AUTOSAR XML (schema 4-0-3)
package /Svc_IoHwAb/CompuMethods
  compu method IoHwAb_Cm_EdgeEnum: 1=IOHWAB_RISING_EDGE (IoHwAb_RisingEdge), 2=IOHWAB_FALLING_EDGE (IoHwAb_FallingEdge), 3=IOHWAB_BOTH_EDGES (IoHwAb_BothEdges)
package /Svc_IoHwAb/ImplementationDataTypes
  20 x impl type:
    IoHwAb_IcuDutyCycleType: category=STRUCTURE
      element ActiveTime: implementation-data-type=IoHwAb_IcuValueType
      element PeriodTime: implementation-data-type=IoHwAb_IcuValueType
    IoHwAb_OcuReturnType: category=VALUE, base-type=uint8
    IoHwAb_GptValueType: category=VALUE, base-type=uint32
    IoHwAb_LengthType: category=VALUE, base-type=uint8
    IoHwAb_OcuValueType: category=VALUE, base-type=uint16
    IoHwAb_ThresholdType: category=VALUE, base-type=uint8
    IoHwAb_IcuEdgeNumberType: category=VALUE, base-type=uint32
    IoHwAb_BoolType: category=VALUE, base-type=uint8, compu {0=IOHWAB_FALSE (IoHwAb_False), 1=IOHWAB_TRUE (IoHwAb_True)}
    IoHwAb_IcuValueType: category=VALUE, base-type=uint32
    IoHwAb_IcuActivationType: category=VALUE, base-type=uint8, compu-method=IoHwAb_Cm_EdgeEnum
    IoHwAb_IcuStateType: category=VALUE, base-type=uint8, compu {0=IOHWAB_IDLE (IoHwAb_Idle), 1=IOHWAB_ACTIVE (IoHwAb_Active)}
    IoHwAb_OcuPinStateType: category=VALUE, base-type=uint8
    IoHwAb_PwmPeriodType: category=VALUE, base-type=uint32
    IoHwAb_IndexType: category=VALUE, base-type=uint16
    IoHwAb_LevelType: category=VALUE, base-type=uint8, compu {0=IOHWAB_LOW (IoHwAb_Low), 1=IOHWAB_HIGH (IoHwAb_High)}
    IoHwAb_ValueType: category=VALUE, base-type=uint16
    IoHwAb_PwmEdgeType: category=VALUE, base-type=uint8, compu-method=IoHwAb_Cm_EdgeEnum
    IoHwAb_IcuIndexType: category=VALUE, base-type=uint16
    IoHwAb_OcuPinActionType: category=VALUE, base-type=uint8
    IoHwAb_StatusType: category=VALUE, base-type=uint8, compu {0=IOHWAB_VOLMON_IoHwAbVoltageMonThreshold0 (IoHwAb_VolMon_IoHwAbVoltageMonThreshold0), 1=IOHWAB_VOLMON_IoHwAbVoltageMonThreshold1 (IoHwAb_VolMon_IoHwAbVoltageMonThreshold1)}
package /Svc_IoHwAb/ClientServerInterfaces
  7 x client server interface, all with is-service=true:
    IoHwAb_If_DigDir
      6 x operation:
        ReadDirect
          arg Level: type=IoHwAb_LevelType, direction=OUT, server-argument-impl-policy=USE-ARGUMENT-TYPE
        WriteDirect
          arg Level: type=IoHwAb_LevelType, direction=IN, server-argument-impl-policy=USE-ARGUMENT-TYPE
        SetToInput
        SetToOutput
        IsInput
          arg blResult: type=IoHwAb_BoolType, direction=OUT, server-argument-impl-policy=USE-ARGUMENT-TYPE
        IsOutput
          arg blResult: type=IoHwAb_BoolType, direction=OUT, server-argument-impl-policy=USE-ARGUMENT-TYPE
    IoHwAb_If_AnaInDir
      operation ReadDirect: possible-error=[IoHwAb_If_AnaInDir/E_BUSY, E_WRONG_LENGTH, E_SETUP_BUFFER_FAIL]
        arg Value: type=IoHwAb_ValueType, direction=OUT, server-argument-impl-policy=USE-ARGUMENT-TYPE
        arg AnaInDirLength: type=IoHwAb_LengthType, direction=IN, server-argument-impl-policy=USE-ARGUMENT-TYPE
      error E_BUSY: error-code=4
      error E_WRONG_LENGTH: error-code=5
      error E_SETUP_BUFFER_FAIL: error-code=6
    IoHwAb_If_AnaIn
      operation Read
        arg Value: type=IoHwAb_ValueType, direction=OUT, server-argument-impl-policy=USE-ARGUMENT-TYPE
      operation Freeze
      operation Unfreeze
      error E_BUSY: error-code=7
    IoHwAb_If_VolMon
      5 x operation:
        Read
          arg Value: type=IoHwAb_ValueType, direction=OUT, server-argument-impl-policy=USE-ARGUMENT-TYPE
        GetStatus
          arg VolMonStatus: type=IoHwAb_StatusType, direction=OUT, server-argument-impl-policy=USE-ARGUMENT-TYPE
        IsThresholdOver
          arg Threshold: type=IoHwAb_ThresholdType, direction=IN, server-argument-impl-policy=USE-ARGUMENT-TYPE
          arg VolMonResult: type=IoHwAb_BoolType, direction=OUT, server-argument-impl-policy=USE-ARGUMENT-TYPE
        IsThresholdUnder
          arg Threshold: type=IoHwAb_ThresholdType, direction=IN, server-argument-impl-policy=USE-ARGUMENT-TYPE
          arg VolMonResult: type=IoHwAb_BoolType, direction=OUT, server-argument-impl-policy=USE-ARGUMENT-TYPE
        Notification
    IoHwAb_If_Icu
      18 x operation:
        SetActivationCondition: possible-error=IoHwAb_If_Icu/E_NOT_SUPPORTED
          arg Activation: type=IoHwAb_IcuActivationType, direction=IN, server-argument-impl-policy=USE-ARGUMENT-TYPE
        DisableNotification: possible-error=IoHwAb_If_Icu/E_NOT_SUPPORTED
        EnableNotification: possible-error=IoHwAb_If_Icu/E_NOT_SUPPORTED
        GetInputState: possible-error=IoHwAb_If_Icu/E_NOT_SUPPORTED
          arg State: type=IoHwAb_IcuStateType, direction=OUT, server-argument-impl-policy=USE-ARGUMENT-TYPE
        StartTimestamp: possible-error=IoHwAb_If_Icu/E_NOT_SUPPORTED
          arg BufPtr: type=IoHwAb_IcuValueType, direction=OUT, server-argument-impl-policy=USE-ARGUMENT-TYPE
          arg BufSize: type=uint16, direction=IN, server-argument-impl-policy=USE-ARGUMENT-TYPE
          arg NotiItv: type=uint16, direction=IN, server-argument-impl-policy=USE-ARGUMENT-TYPE
        StopTimestamp: possible-error=IoHwAb_If_Icu/E_NOT_SUPPORTED
        GetTimestampIndex: possible-error=IoHwAb_If_Icu/E_NOT_SUPPORTED
          arg TimestampIdx: type=IoHwAb_IcuIndexType, direction=OUT, server-argument-impl-policy=USE-ARGUMENT-TYPE
        ResetEdgeCount: possible-error=IoHwAb_If_Icu/E_NOT_SUPPORTED
        EnableEdgeCount: possible-error=IoHwAb_If_Icu/E_NOT_SUPPORTED
        DisableEdgeCount: possible-error=IoHwAb_If_Icu/E_NOT_SUPPORTED
        GetEdgeNumbers: possible-error=IoHwAb_If_Icu/E_NOT_SUPPORTED
          arg Num: type=IoHwAb_IcuEdgeNumberType, direction=OUT, server-argument-impl-policy=USE-ARGUMENT-TYPE
        EnableEdgeDetection: possible-error=IoHwAb_If_Icu/E_NOT_SUPPORTED
        DisableEdgeDetection: possible-error=IoHwAb_If_Icu/E_NOT_SUPPORTED
        StartSignalMeasurement: possible-error=IoHwAb_If_Icu/E_NOT_SUPPORTED
        StopSignalMeasurement: possible-error=IoHwAb_If_Icu/E_NOT_SUPPORTED
        GetTimeElapsed: possible-error=IoHwAb_If_Icu/E_NOT_SUPPORTED
          arg Time: type=IoHwAb_IcuValueType, direction=OUT, server-argument-impl-policy=USE-ARGUMENT-TYPE
        GetDutyCycleValues: possible-error=IoHwAb_If_Icu/E_NOT_SUPPORTED
          arg DutyCycle: type=IoHwAb_IcuDutyCycleType, direction=OUT, server-argument-impl-policy=USE-ARGUMENT-TYPE
        Notification
      error E_NOT_SUPPORTED: error-code=9
    IoHwAb_If_Gpt
      7 x operation:
        StartTimer: possible-error=IoHwAb_If_Gpt/E_NOT_SUPPORTED
          arg Value: type=IoHwAb_GptValueType, direction=IN, server-argument-impl-policy=USE-ARGUMENT-TYPE
        StopTimer: possible-error=IoHwAb_If_Gpt/E_NOT_SUPPORTED
        GetTimeElapsed: possible-error=IoHwAb_If_Gpt/E_NOT_SUPPORTED
          arg Value: type=IoHwAb_GptValueType, direction=OUT, server-argument-impl-policy=USE-ARGUMENT-TYPE
        GetTimeRemaining: possible-error=IoHwAb_If_Gpt/E_NOT_SUPPORTED
          arg Value: type=IoHwAb_GptValueType, direction=OUT, server-argument-impl-policy=USE-ARGUMENT-TYPE
        DisableNotification: possible-error=IoHwAb_If_Gpt/E_NOT_SUPPORTED
        EnableNotification: possible-error=IoHwAb_If_Gpt/E_NOT_SUPPORTED
        Notification
      error E_NOT_SUPPORTED: error-code=10
    IoHwAb_If_Pwm
      6 x operation, all with possible-error=IoHwAb_If_Pwm/E_NOT_SUPPORTED:
        SetDutyCycle
          arg Duty: type=uint16, direction=IN, server-argument-impl-policy=USE-ARGUMENT-TYPE
        SetPeriodAndDuty
          arg Period: type=IoHwAb_PwmPeriodType, direction=IN, server-argument-impl-policy=USE-ARGUMENT-TYPE
          arg Duty: type=uint16, direction=IN, server-argument-impl-policy=USE-ARGUMENT-TYPE
        SetOutputToIdle
        GetOutputState
          arg Level: type=IoHwAb_LevelType, direction=OUT, server-argument-impl-policy=USE-ARGUMENT-TYPE
        DisableNotification
        EnableNotification
          arg NotificationEdge: type=IoHwAb_PwmEdgeType, direction=IN, server-argument-impl-policy=USE-ARGUMENT-TYPE
      error E_NOT_SUPPORTED: error-code=11
package /Svc_IoHwAb/EcuAbstractionSwComponentTypes
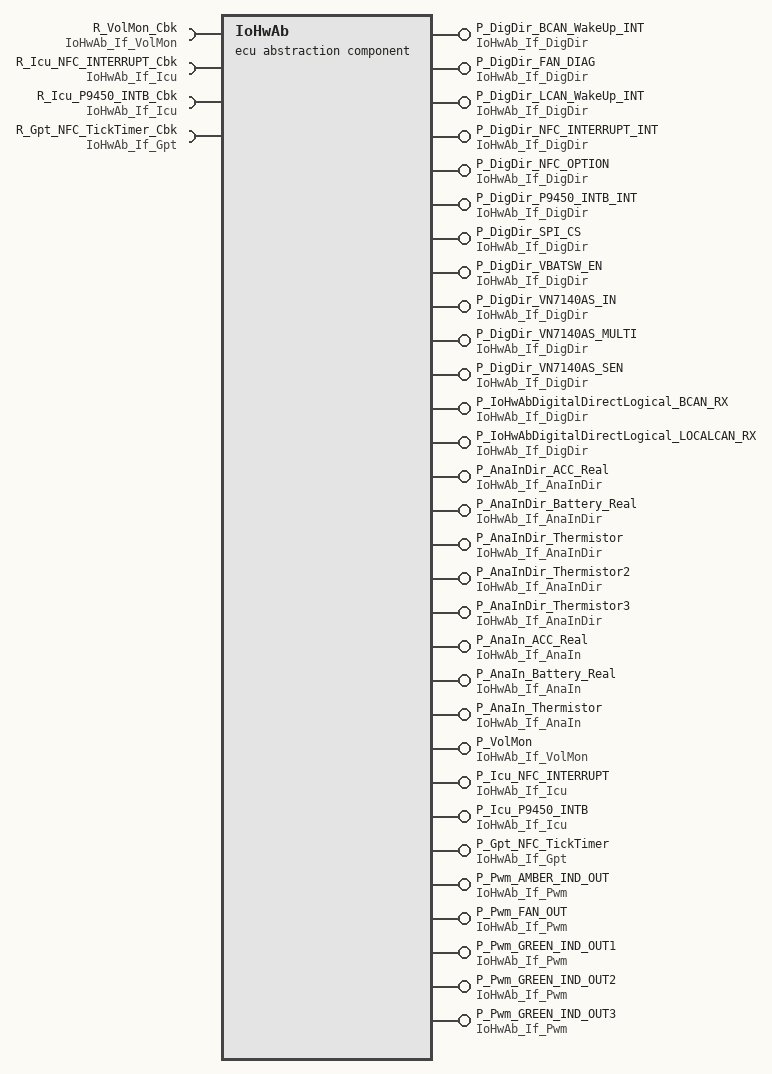
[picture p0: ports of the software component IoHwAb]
  ecu abstraction sw component type IoHwAb
    22 x provide port:
      P_DigDir_BCAN_WakeUp_INT: provided-interface=IoHwAb_If_DigDir
        provided-com-specs:
          operation=IoHwAb_If_DigDir/ReadDirect, queue-length=1
          operation=WriteDirect, queue-length=1
          operation=SetToInput, queue-length=1
          operation=SetToOutput, queue-length=1
          operation=IsInput, queue-length=1
          operation=IsOutput, queue-length=1
      P_DigDir_FAN_DIAG: provided-interface=IoHwAb_If_DigDir
        provided-com-specs:
          operation=IoHwAb_If_DigDir/ReadDirect, queue-length=1
          operation=WriteDirect, queue-length=1
          operation=SetToInput, queue-length=1
          operation=SetToOutput, queue-length=1
          operation=IsInput, queue-length=1
          operation=IsOutput, queue-length=1
      P_DigDir_LCAN_WakeUp_INT: provided-interface=IoHwAb_If_DigDir
        provided-com-specs:
          operation=IoHwAb_If_DigDir/ReadDirect, queue-length=1
          operation=WriteDirect, queue-length=1
          operation=SetToInput, queue-length=1
          operation=SetToOutput, queue-length=1
          operation=IsInput, queue-length=1
          operation=IsOutput, queue-length=1
      P_DigDir_NFC_INTERRUPT_INT: provided-interface=IoHwAb_If_DigDir
        provided-com-specs:
          operation=IoHwAb_If_DigDir/ReadDirect, queue-length=1
          operation=WriteDirect, queue-length=1
          operation=SetToInput, queue-length=1
          operation=SetToOutput, queue-length=1
          operation=IsInput, queue-length=1
          operation=IsOutput, queue-length=1
      P_DigDir_NFC_OPTION: provided-interface=IoHwAb_If_DigDir
        provided-com-specs:
          operation=IoHwAb_If_DigDir/ReadDirect, queue-length=1
          operation=WriteDirect, queue-length=1
          operation=SetToInput, queue-length=1
          operation=SetToOutput, queue-length=1
          operation=IsInput, queue-length=1
          operation=IsOutput, queue-length=1
      P_DigDir_P9450_INTB_INT: provided-interface=IoHwAb_If_DigDir
        provided-com-specs:
          operation=IoHwAb_If_DigDir/ReadDirect, queue-length=1
          operation=WriteDirect, queue-length=1
          operation=SetToInput, queue-length=1
          operation=SetToOutput, queue-length=1
          operation=IsInput, queue-length=1
          operation=IsOutput, queue-length=1
      P_DigDir_SPI_CS: provided-interface=IoHwAb_If_DigDir
        provided-com-specs:
          operation=IoHwAb_If_DigDir/ReadDirect, queue-length=1
          operation=WriteDirect, queue-length=1
          operation=SetToInput, queue-length=1
          operation=SetToOutput, queue-length=1
          operation=IsInput, queue-length=1
          operation=IsOutput, queue-length=1
      P_DigDir_VBATSW_EN: provided-interface=IoHwAb_If_DigDir
        provided-com-specs:
          operation=IoHwAb_If_DigDir/ReadDirect, queue-length=1
          operation=WriteDirect, queue-length=1
          operation=SetToInput, queue-length=1
          operation=SetToOutput, queue-length=1
          operation=IsInput, queue-length=1
          operation=IsOutput, queue-length=1
      P_DigDir_VN7140AS_IN: provided-interface=IoHwAb_If_DigDir
        provided-com-specs:
          operation=IoHwAb_If_DigDir/ReadDirect, queue-length=1
          operation=WriteDirect, queue-length=1
          operation=SetToInput, queue-length=1
          operation=SetToOutput, queue-length=1
          operation=IsInput, queue-length=1
          operation=IsOutput, queue-length=1
      P_DigDir_VN7140AS_MULTI: provided-interface=IoHwAb_If_DigDir
        provided-com-specs:
          operation=IoHwAb_If_DigDir/ReadDirect, queue-length=1
          operation=WriteDirect, queue-length=1
          operation=SetToInput, queue-length=1
          operation=SetToOutput, queue-length=1
          operation=IsInput, queue-length=1
          operation=IsOutput, queue-length=1
      P_DigDir_VN7140AS_SEN: provided-interface=IoHwAb_If_DigDir
        provided-com-specs:
          operation=IoHwAb_If_DigDir/ReadDirect, queue-length=1
          operation=WriteDirect, queue-length=1
          operation=SetToInput, queue-length=1
          operation=SetToOutput, queue-length=1
          operation=IsInput, queue-length=1
          operation=IsOutput, queue-length=1
      P_IoHwAbDigitalDirectLogical_BCAN_RX: provided-interface=IoHwAb_If_DigDir
        provided-com-specs:
          operation=IoHwAb_If_DigDir/ReadDirect, queue-length=1
          operation=WriteDirect, queue-length=1
          operation=SetToInput, queue-length=1
          operation=SetToOutput, queue-length=1
          operation=IsInput, queue-length=1
          operation=IsOutput, queue-length=1
      P_IoHwAbDigitalDirectLogical_LOCALCAN_RX: provided-interface=IoHwAb_If_DigDir
        provided-com-specs:
          operation=IoHwAb_If_DigDir/ReadDirect, queue-length=1
          operation=WriteDirect, queue-length=1
          operation=SetToInput, queue-length=1
          operation=SetToOutput, queue-length=1
          operation=IsInput, queue-length=1
          operation=IsOutput, queue-length=1
      P_AnaInDir_ACC_Real: server-com-spec{operation=IoHwAb_If_AnaInDir/ReadDirect, queue-length=1}, provided-interface=IoHwAb_If_AnaInDir
      P_AnaInDir_Battery_Real: server-com-spec{operation=IoHwAb_If_AnaInDir/ReadDirect, queue-length=1}, provided-interface=IoHwAb_If_AnaInDir
      P_AnaInDir_Thermistor: server-com-spec{operation=IoHwAb_If_AnaInDir/ReadDirect, queue-length=1}, provided-interface=IoHwAb_If_AnaInDir
      P_AnaInDir_Thermistor2: server-com-spec{operation=IoHwAb_If_AnaInDir/ReadDirect, queue-length=1}, provided-interface=IoHwAb_If_AnaInDir
      P_AnaInDir_Thermistor3: server-com-spec{operation=IoHwAb_If_AnaInDir/ReadDirect, queue-length=1}, provided-interface=IoHwAb_If_AnaInDir
      P_AnaIn_ACC_Real: provided-interface=IoHwAb_If_AnaIn
        provided-com-specs:
          operation=IoHwAb_If_AnaIn/Read, queue-length=1
          operation=Freeze, queue-length=1
          operation=Unfreeze, queue-length=1
      P_AnaIn_Battery_Real: provided-interface=IoHwAb_If_AnaIn
        provided-com-specs:
          operation=IoHwAb_If_AnaIn/Read, queue-length=1
          operation=Freeze, queue-length=1
          operation=Unfreeze, queue-length=1
      P_AnaIn_Thermistor: provided-interface=IoHwAb_If_AnaIn
        provided-com-specs:
          operation=IoHwAb_If_AnaIn/Read, queue-length=1
          operation=Freeze, queue-length=1
          operation=Unfreeze, queue-length=1
      P_VolMon: provided-interface=IoHwAb_If_VolMon
        provided-com-specs:
          operation=IoHwAb_If_VolMon/Read, queue-length=1
          operation=GetStatus, queue-length=1
          operation=IsThresholdOver, queue-length=1
          operation=IsThresholdUnder, queue-length=1
    require port R_VolMon_Cbk: client-com-spec=IoHwAb_If_VolMon/Notification, required-interface=IoHwAb_If_VolMon
    provide port P_Icu_NFC_INTERRUPT: provided-interface=IoHwAb_If_Icu
      provided-com-specs:
        operation=SetActivationCondition, queue-length=1
        operation=IoHwAb_If_Icu/DisableNotification, queue-length=1
        operation=IoHwAb_If_Icu/EnableNotification, queue-length=1
        operation=GetInputState, queue-length=1
        operation=StartTimestamp, queue-length=1
        operation=StopTimestamp, queue-length=1
        operation=GetTimestampIndex, queue-length=1
        operation=ResetEdgeCount, queue-length=1
        operation=EnableEdgeCount, queue-length=1
        operation=DisableEdgeCount, queue-length=1
        operation=GetEdgeNumbers, queue-length=1
        operation=EnableEdgeDetection, queue-length=1
        operation=DisableEdgeDetection, queue-length=1
        operation=StartSignalMeasurement, queue-length=1
        operation=StopSignalMeasurement, queue-length=1
        operation=IoHwAb_If_Icu/GetTimeElapsed, queue-length=1
        operation=GetDutyCycleValues, queue-length=1
    require port R_Icu_NFC_INTERRUPT_Cbk: client-com-spec=IoHwAb_If_Icu/Notification, required-interface=IoHwAb_If_Icu
    provide port P_Icu_P9450_INTB: provided-interface=IoHwAb_If_Icu
      provided-com-specs:
        operation=SetActivationCondition, queue-length=1
        operation=IoHwAb_If_Icu/DisableNotification, queue-length=1
        operation=IoHwAb_If_Icu/EnableNotification, queue-length=1
        operation=GetInputState, queue-length=1
        operation=StartTimestamp, queue-length=1
        operation=StopTimestamp, queue-length=1
        operation=GetTimestampIndex, queue-length=1
        operation=ResetEdgeCount, queue-length=1
        operation=EnableEdgeCount, queue-length=1
        operation=DisableEdgeCount, queue-length=1
        operation=GetEdgeNumbers, queue-length=1
        operation=EnableEdgeDetection, queue-length=1
        operation=DisableEdgeDetection, queue-length=1
        operation=StartSignalMeasurement, queue-length=1
        operation=StopSignalMeasurement, queue-length=1
        operation=IoHwAb_If_Icu/GetTimeElapsed, queue-length=1
        operation=GetDutyCycleValues, queue-length=1
    require port R_Icu_P9450_INTB_Cbk: client-com-spec=IoHwAb_If_Icu/Notification, required-interface=IoHwAb_If_Icu
    provide port P_Gpt_NFC_TickTimer: provided-interface=IoHwAb_If_Gpt
      provided-com-specs:
        operation=StartTimer, queue-length=1
        operation=StopTimer, queue-length=1
        operation=IoHwAb_If_Gpt/GetTimeElapsed, queue-length=1
        operation=GetTimeRemaining, queue-length=1
        operation=IoHwAb_If_Gpt/DisableNotification, queue-length=1
        operation=IoHwAb_If_Gpt/EnableNotification, queue-length=1
    require port R_Gpt_NFC_TickTimer_Cbk: client-com-spec=IoHwAb_If_Gpt/Notification, required-interface=IoHwAb_If_Gpt
    5 x provide port, all with provided-interface=IoHwAb_If_Pwm:
      P_Pwm_AMBER_IND_OUT
        provided-com-specs:
          operation=SetDutyCycle, queue-length=1
          operation=SetPeriodAndDuty, queue-length=1
          operation=SetOutputToIdle, queue-length=1
          operation=GetOutputState, queue-length=1
          operation=IoHwAb_If_Pwm/DisableNotification, queue-length=1
          operation=IoHwAb_If_Pwm/EnableNotification, queue-length=1
      P_Pwm_FAN_OUT
        provided-com-specs:
          operation=SetDutyCycle, queue-length=1
          operation=SetPeriodAndDuty, queue-length=1
          operation=SetOutputToIdle, queue-length=1
          operation=GetOutputState, queue-length=1
          operation=IoHwAb_If_Pwm/DisableNotification, queue-length=1
          operation=IoHwAb_If_Pwm/EnableNotification, queue-length=1
      P_Pwm_GREEN_IND_OUT1
        provided-com-specs:
          operation=SetDutyCycle, queue-length=1
          operation=SetPeriodAndDuty, queue-length=1
          operation=SetOutputToIdle, queue-length=1
          operation=GetOutputState, queue-length=1
          operation=IoHwAb_If_Pwm/DisableNotification, queue-length=1
          operation=IoHwAb_If_Pwm/EnableNotification, queue-length=1
      P_Pwm_GREEN_IND_OUT2
        provided-com-specs:
          operation=SetDutyCycle, queue-length=1
          operation=SetPeriodAndDuty, queue-length=1
          operation=SetOutputToIdle, queue-length=1
          operation=GetOutputState, queue-length=1
          operation=IoHwAb_If_Pwm/DisableNotification, queue-length=1
          operation=IoHwAb_If_Pwm/EnableNotification, queue-length=1
      P_Pwm_GREEN_IND_OUT3
        provided-com-specs:
          operation=SetDutyCycle, queue-length=1
          operation=SetPeriodAndDuty, queue-length=1
          operation=SetOutputToIdle, queue-length=1
          operation=GetOutputState, queue-length=1
          operation=IoHwAb_If_Pwm/DisableNotification, queue-length=1
          operation=IoHwAb_If_Pwm/EnableNotification, queue-length=1
    behavior IB_IoHwAb
      166 x operation invoked event:
        IoHwAb_Ev_DigDir_BCAN_WakeUp_INT_ReadDirect: start-on-event=IoHwAb_Re_DigDir_ReadDirect, operation=P_DigDir_BCAN_WakeUp_INT.ReadDirect
        IoHwAb_Ev_DigDir_BCAN_WakeUp_INT_WriteDirect: start-on-event=IoHwAb_Re_DigDir_WriteDirect, operation=P_DigDir_BCAN_WakeUp_INT.WriteDirect
        IoHwAb_Ev_DigDir_BCAN_WakeUp_INT_SetToInput: start-on-event=IoHwAb_Re_DigDir_SetToInput, operation=P_DigDir_BCAN_WakeUp_INT.SetToInput
        IoHwAb_Ev_DigDir_BCAN_WakeUp_INT_SetToOutput: start-on-event=IoHwAb_Re_DigDir_SetToOutput, operation=P_DigDir_BCAN_WakeUp_INT.SetToOutput
        IoHwAb_Ev_DigDir_BCAN_WakeUp_INT_IsInput: start-on-event=IoHwAb_Re_DigDir_IsInput, operation=P_DigDir_BCAN_WakeUp_INT.IsInput
        IoHwAb_Ev_DigDir_BCAN_WakeUp_INT_IsOutput: start-on-event=IoHwAb_Re_DigDir_IsOutput, operation=P_DigDir_BCAN_WakeUp_INT.IsOutput
        IoHwAb_Ev_DigDir_FAN_DIAG_ReadDirect: start-on-event=IoHwAb_Re_DigDir_ReadDirect, operation=P_DigDir_FAN_DIAG.ReadDirect
        IoHwAb_Ev_DigDir_FAN_DIAG_WriteDirect: start-on-event=IoHwAb_Re_DigDir_WriteDirect, operation=P_DigDir_FAN_DIAG.WriteDirect
        IoHwAb_Ev_DigDir_FAN_DIAG_SetToInput: start-on-event=IoHwAb_Re_DigDir_SetToInput, operation=P_DigDir_FAN_DIAG.SetToInput
        IoHwAb_Ev_DigDir_FAN_DIAG_SetToOutput: start-on-event=IoHwAb_Re_DigDir_SetToOutput, operation=P_DigDir_FAN_DIAG.SetToOutput
        IoHwAb_Ev_DigDir_FAN_DIAG_IsInput: start-on-event=IoHwAb_Re_DigDir_IsInput, operation=P_DigDir_FAN_DIAG.IsInput
        IoHwAb_Ev_DigDir_FAN_DIAG_IsOutput: start-on-event=IoHwAb_Re_DigDir_IsOutput, operation=P_DigDir_FAN_DIAG.IsOutput
        IoHwAb_Ev_DigDir_LCAN_WakeUp_INT_ReadDirect: start-on-event=IoHwAb_Re_DigDir_ReadDirect, operation=P_DigDir_LCAN_WakeUp_INT.ReadDirect
        IoHwAb_Ev_DigDir_LCAN_WakeUp_INT_WriteDirect: start-on-event=IoHwAb_Re_DigDir_WriteDirect, operation=P_DigDir_LCAN_WakeUp_INT.WriteDirect
        IoHwAb_Ev_DigDir_LCAN_WakeUp_INT_SetToInput: start-on-event=IoHwAb_Re_DigDir_SetToInput, operation=P_DigDir_LCAN_WakeUp_INT.SetToInput
        IoHwAb_Ev_DigDir_LCAN_WakeUp_INT_SetToOutput: start-on-event=IoHwAb_Re_DigDir_SetToOutput, operation=P_DigDir_LCAN_WakeUp_INT.SetToOutput
        IoHwAb_Ev_DigDir_LCAN_WakeUp_INT_IsInput: start-on-event=IoHwAb_Re_DigDir_IsInput, operation=P_DigDir_LCAN_WakeUp_INT.IsInput
        IoHwAb_Ev_DigDir_LCAN_WakeUp_INT_IsOutput: start-on-event=IoHwAb_Re_DigDir_IsOutput, operation=P_DigDir_LCAN_WakeUp_INT.IsOutput
        IoHwAb_Ev_DigDir_NFC_INTERRUPT_INT_ReadDirect: start-on-event=IoHwAb_Re_DigDir_ReadDirect, operation=P_DigDir_NFC_INTERRUPT_INT.ReadDirect
        IoHwAb_Ev_DigDir_NFC_INTERRUPT_INT_WriteDirect: start-on-event=IoHwAb_Re_DigDir_WriteDirect, operation=P_DigDir_NFC_INTERRUPT_INT.WriteDirect
        IoHwAb_Ev_DigDir_NFC_INTERRUPT_INT_SetToInput: start-on-event=IoHwAb_Re_DigDir_SetToInput, operation=P_DigDir_NFC_INTERRUPT_INT.SetToInput
        IoHwAb_Ev_DigDir_NFC_INTERRUPT_INT_SetToOutput: start-on-event=IoHwAb_Re_DigDir_SetToOutput, operation=P_DigDir_NFC_INTERRUPT_INT.SetToOutput
        IoHwAb_Ev_DigDir_NFC_INTERRUPT_INT_IsInput: start-on-event=IoHwAb_Re_DigDir_IsInput, operation=P_DigDir_NFC_INTERRUPT_INT.IsInput
        IoHwAb_Ev_DigDir_NFC_INTERRUPT_INT_IsOutput: start-on-event=IoHwAb_Re_DigDir_IsOutput, operation=P_DigDir_NFC_INTERRUPT_INT.IsOutput
        IoHwAb_Ev_DigDir_NFC_OPTION_ReadDirect: start-on-event=IoHwAb_Re_DigDir_ReadDirect, operation=P_DigDir_NFC_OPTION.ReadDirect
        IoHwAb_Ev_DigDir_NFC_OPTION_WriteDirect: start-on-event=IoHwAb_Re_DigDir_WriteDirect, operation=P_DigDir_NFC_OPTION.WriteDirect
        IoHwAb_Ev_DigDir_NFC_OPTION_SetToInput: start-on-event=IoHwAb_Re_DigDir_SetToInput, operation=P_DigDir_NFC_OPTION.SetToInput
        IoHwAb_Ev_DigDir_NFC_OPTION_SetToOutput: start-on-event=IoHwAb_Re_DigDir_SetToOutput, operation=P_DigDir_NFC_OPTION.SetToOutput
        IoHwAb_Ev_DigDir_NFC_OPTION_IsInput: start-on-event=IoHwAb_Re_DigDir_IsInput, operation=P_DigDir_NFC_OPTION.IsInput
        IoHwAb_Ev_DigDir_NFC_OPTION_IsOutput: start-on-event=IoHwAb_Re_DigDir_IsOutput, operation=P_DigDir_NFC_OPTION.IsOutput
        IoHwAb_Ev_DigDir_P9450_INTB_INT_ReadDirect: start-on-event=IoHwAb_Re_DigDir_ReadDirect, operation=P_DigDir_P9450_INTB_INT.ReadDirect
        IoHwAb_Ev_DigDir_P9450_INTB_INT_WriteDirect: start-on-event=IoHwAb_Re_DigDir_WriteDirect, operation=P_DigDir_P9450_INTB_INT.WriteDirect
        IoHwAb_Ev_DigDir_P9450_INTB_INT_SetToInput: start-on-event=IoHwAb_Re_DigDir_SetToInput, operation=P_DigDir_P9450_INTB_INT.SetToInput
        IoHwAb_Ev_DigDir_P9450_INTB_INT_SetToOutput: start-on-event=IoHwAb_Re_DigDir_SetToOutput, operation=P_DigDir_P9450_INTB_INT.SetToOutput
        IoHwAb_Ev_DigDir_P9450_INTB_INT_IsInput: start-on-event=IoHwAb_Re_DigDir_IsInput, operation=P_DigDir_P9450_INTB_INT.IsInput
        IoHwAb_Ev_DigDir_P9450_INTB_INT_IsOutput: start-on-event=IoHwAb_Re_DigDir_IsOutput, operation=P_DigDir_P9450_INTB_INT.IsOutput
        IoHwAb_Ev_DigDir_SPI_CS_ReadDirect: start-on-event=IoHwAb_Re_DigDir_ReadDirect, operation=P_DigDir_SPI_CS.ReadDirect
        IoHwAb_Ev_DigDir_SPI_CS_WriteDirect: start-on-event=IoHwAb_Re_DigDir_WriteDirect, operation=P_DigDir_SPI_CS.WriteDirect
        IoHwAb_Ev_DigDir_SPI_CS_SetToInput: start-on-event=IoHwAb_Re_DigDir_SetToInput, operation=P_DigDir_SPI_CS.SetToInput
        IoHwAb_Ev_DigDir_SPI_CS_SetToOutput: start-on-event=IoHwAb_Re_DigDir_SetToOutput, operation=P_DigDir_SPI_CS.SetToOutput
        IoHwAb_Ev_DigDir_SPI_CS_IsInput: start-on-event=IoHwAb_Re_DigDir_IsInput, operation=P_DigDir_SPI_CS.IsInput
        IoHwAb_Ev_DigDir_SPI_CS_IsOutput: start-on-event=IoHwAb_Re_DigDir_IsOutput, operation=P_DigDir_SPI_CS.IsOutput
        IoHwAb_Ev_DigDir_VBATSW_EN_ReadDirect: start-on-event=IoHwAb_Re_DigDir_ReadDirect, operation=P_DigDir_VBATSW_EN.ReadDirect
        IoHwAb_Ev_DigDir_VBATSW_EN_WriteDirect: start-on-event=IoHwAb_Re_DigDir_WriteDirect, operation=P_DigDir_VBATSW_EN.WriteDirect
        IoHwAb_Ev_DigDir_VBATSW_EN_SetToInput: start-on-event=IoHwAb_Re_DigDir_SetToInput, operation=P_DigDir_VBATSW_EN.SetToInput
        IoHwAb_Ev_DigDir_VBATSW_EN_SetToOutput: start-on-event=IoHwAb_Re_DigDir_SetToOutput, operation=P_DigDir_VBATSW_EN.SetToOutput
        IoHwAb_Ev_DigDir_VBATSW_EN_IsInput: start-on-event=IoHwAb_Re_DigDir_IsInput, operation=P_DigDir_VBATSW_EN.IsInput
        IoHwAb_Ev_DigDir_VBATSW_EN_IsOutput: start-on-event=IoHwAb_Re_DigDir_IsOutput, operation=P_DigDir_VBATSW_EN.IsOutput
        IoHwAb_Ev_DigDir_VN7140AS_IN_ReadDirect: start-on-event=IoHwAb_Re_DigDir_ReadDirect, operation=P_DigDir_VN7140AS_IN.ReadDirect
        IoHwAb_Ev_DigDir_VN7140AS_IN_WriteDirect: start-on-event=IoHwAb_Re_DigDir_WriteDirect, operation=P_DigDir_VN7140AS_IN.WriteDirect
        IoHwAb_Ev_DigDir_VN7140AS_IN_SetToInput: start-on-event=IoHwAb_Re_DigDir_SetToInput, operation=P_DigDir_VN7140AS_IN.SetToInput
        IoHwAb_Ev_DigDir_VN7140AS_IN_SetToOutput: start-on-event=IoHwAb_Re_DigDir_SetToOutput, operation=P_DigDir_VN7140AS_IN.SetToOutput
        IoHwAb_Ev_DigDir_VN7140AS_IN_IsInput: start-on-event=IoHwAb_Re_DigDir_IsInput, operation=P_DigDir_VN7140AS_IN.IsInput
        IoHwAb_Ev_DigDir_VN7140AS_IN_IsOutput: start-on-event=IoHwAb_Re_DigDir_IsOutput, operation=P_DigDir_VN7140AS_IN.IsOutput
        IoHwAb_Ev_DigDir_VN7140AS_MULTI_ReadDirect: start-on-event=IoHwAb_Re_DigDir_ReadDirect, operation=P_DigDir_VN7140AS_MULTI.ReadDirect
        IoHwAb_Ev_DigDir_VN7140AS_MULTI_WriteDirect: start-on-event=IoHwAb_Re_DigDir_WriteDirect, operation=P_DigDir_VN7140AS_MULTI.WriteDirect
        IoHwAb_Ev_DigDir_VN7140AS_MULTI_SetToInput: start-on-event=IoHwAb_Re_DigDir_SetToInput, operation=P_DigDir_VN7140AS_MULTI.SetToInput
        IoHwAb_Ev_DigDir_VN7140AS_MULTI_SetToOutput: start-on-event=IoHwAb_Re_DigDir_SetToOutput, operation=P_DigDir_VN7140AS_MULTI.SetToOutput
        IoHwAb_Ev_DigDir_VN7140AS_MULTI_IsInput: start-on-event=IoHwAb_Re_DigDir_IsInput, operation=P_DigDir_VN7140AS_MULTI.IsInput
        IoHwAb_Ev_DigDir_VN7140AS_MULTI_IsOutput: start-on-event=IoHwAb_Re_DigDir_IsOutput, operation=P_DigDir_VN7140AS_MULTI.IsOutput
        IoHwAb_Ev_DigDir_VN7140AS_SEN_ReadDirect: start-on-event=IoHwAb_Re_DigDir_ReadDirect, operation=P_DigDir_VN7140AS_SEN.ReadDirect
        IoHwAb_Ev_DigDir_VN7140AS_SEN_WriteDirect: start-on-event=IoHwAb_Re_DigDir_WriteDirect, operation=P_DigDir_VN7140AS_SEN.WriteDirect
        IoHwAb_Ev_DigDir_VN7140AS_SEN_SetToInput: start-on-event=IoHwAb_Re_DigDir_SetToInput, operation=P_DigDir_VN7140AS_SEN.SetToInput
        IoHwAb_Ev_DigDir_VN7140AS_SEN_SetToOutput: start-on-event=IoHwAb_Re_DigDir_SetToOutput, operation=P_DigDir_VN7140AS_SEN.SetToOutput
        IoHwAb_Ev_DigDir_VN7140AS_SEN_IsInput: start-on-event=IoHwAb_Re_DigDir_IsInput, operation=P_DigDir_VN7140AS_SEN.IsInput
        IoHwAb_Ev_DigDir_VN7140AS_SEN_IsOutput: start-on-event=IoHwAb_Re_DigDir_IsOutput, operation=P_DigDir_VN7140AS_SEN.IsOutput
        IoHwAb_Ev_IoHwAbDigitalDirectLogical_BCAN_RX_ReadDirect: start-on-event=IoHwAb_Re_DigDir_ReadDirect, operation=P_IoHwAbDigitalDirectLogical_BCAN_RX.ReadDirect
        IoHwAb_Ev_IoHwAbDigitalDirectLogical_BCAN_RX_WriteDirect: start-on-event=IoHwAb_Re_DigDir_WriteDirect, operation=P_IoHwAbDigitalDirectLogical_BCAN_RX.WriteDirect
        IoHwAb_Ev_IoHwAbDigitalDirectLogical_BCAN_RX_SetToInput: start-on-event=IoHwAb_Re_DigDir_SetToInput, operation=P_IoHwAbDigitalDirectLogical_BCAN_RX.SetToInput
        IoHwAb_Ev_IoHwAbDigitalDirectLogical_BCAN_RX_SetToOutput: start-on-event=IoHwAb_Re_DigDir_SetToOutput, operation=P_IoHwAbDigitalDirectLogical_BCAN_RX.SetToOutput
        IoHwAb_Ev_IoHwAbDigitalDirectLogical_BCAN_RX_IsInput: start-on-event=IoHwAb_Re_DigDir_IsInput, operation=P_IoHwAbDigitalDirectLogical_BCAN_RX.IsInput
        IoHwAb_Ev_IoHwAbDigitalDirectLogical_BCAN_RX_IsOutput: start-on-event=IoHwAb_Re_DigDir_IsOutput, operation=P_IoHwAbDigitalDirectLogical_BCAN_RX.IsOutput
        IoHwAb_Ev_IoHwAbDigitalDirectLogical_LOCALCAN_RX_ReadDirect: start-on-event=IoHwAb_Re_DigDir_ReadDirect, operation=P_IoHwAbDigitalDirectLogical_LOCALCAN_RX.ReadDirect
        IoHwAb_Ev_IoHwAbDigitalDirectLogical_LOCALCAN_RX_WriteDirect: start-on-event=IoHwAb_Re_DigDir_WriteDirect, operation=P_IoHwAbDigitalDirectLogical_LOCALCAN_RX.WriteDirect
        IoHwAb_Ev_IoHwAbDigitalDirectLogical_LOCALCAN_RX_SetToInput: start-on-event=IoHwAb_Re_DigDir_SetToInput, operation=P_IoHwAbDigitalDirectLogical_LOCALCAN_RX.SetToInput
        IoHwAb_Ev_IoHwAbDigitalDirectLogical_LOCALCAN_RX_SetToOutput: start-on-event=IoHwAb_Re_DigDir_SetToOutput, operation=P_IoHwAbDigitalDirectLogical_LOCALCAN_RX.SetToOutput
        IoHwAb_Ev_IoHwAbDigitalDirectLogical_LOCALCAN_RX_IsInput: start-on-event=IoHwAb_Re_DigDir_IsInput, operation=P_IoHwAbDigitalDirectLogical_LOCALCAN_RX.IsInput
        IoHwAb_Ev_IoHwAbDigitalDirectLogical_LOCALCAN_RX_IsOutput: start-on-event=IoHwAb_Re_DigDir_IsOutput, operation=P_IoHwAbDigitalDirectLogical_LOCALCAN_RX.IsOutput
        IoHwAb_Ev_AnaInDir_ACC_Real_ReadDirect: start-on-event=IoHwAb_Re_AnaInDir_ReadDirect, operation=P_AnaInDir_ACC_Real.ReadDirect
        IoHwAb_Ev_AnaInDir_Battery_Real_ReadDirect: start-on-event=IoHwAb_Re_AnaInDir_ReadDirect, operation=P_AnaInDir_Battery_Real.ReadDirect
        IoHwAb_Ev_AnaInDir_Thermistor_ReadDirect: start-on-event=IoHwAb_Re_AnaInDir_ReadDirect, operation=P_AnaInDir_Thermistor.ReadDirect
        IoHwAb_Ev_AnaInDir_Thermistor2_ReadDirect: start-on-event=IoHwAb_Re_AnaInDir_ReadDirect, operation=P_AnaInDir_Thermistor2.ReadDirect
        IoHwAb_Ev_AnaInDir_Thermistor3_ReadDirect: start-on-event=IoHwAb_Re_AnaInDir_ReadDirect, operation=P_AnaInDir_Thermistor3.ReadDirect
        IoHwAb_Ev_AnaIn_ACC_Real_Read: start-on-event=IoHwAb_Re_AnaIn_Read, operation=P_AnaIn_ACC_Real.Read
        IoHwAb_Ev_AnaIn_ACC_Real_Freeze: start-on-event=IoHwAb_Re_AnaIn_Freeze, operation=P_AnaIn_ACC_Real.Freeze
        IoHwAb_Ev_AnaIn_ACC_Real_Unfreeze: start-on-event=IoHwAb_Re_AnaIn_Unfreeze, operation=P_AnaIn_ACC_Real.Unfreeze
        IoHwAb_Ev_AnaIn_Battery_Real_Read: start-on-event=IoHwAb_Re_AnaIn_Read, operation=P_AnaIn_Battery_Real.Read
        IoHwAb_Ev_AnaIn_Battery_Real_Freeze: start-on-event=IoHwAb_Re_AnaIn_Freeze, operation=P_AnaIn_Battery_Real.Freeze
        IoHwAb_Ev_AnaIn_Battery_Real_Unfreeze: start-on-event=IoHwAb_Re_AnaIn_Unfreeze, operation=P_AnaIn_Battery_Real.Unfreeze
        IoHwAb_Ev_AnaIn_Thermistor_Read: start-on-event=IoHwAb_Re_AnaIn_Read, operation=P_AnaIn_Thermistor.Read
        IoHwAb_Ev_AnaIn_Thermistor_Freeze: start-on-event=IoHwAb_Re_AnaIn_Freeze, operation=P_AnaIn_Thermistor.Freeze
        IoHwAb_Ev_AnaIn_Thermistor_Unfreeze: start-on-event=IoHwAb_Re_AnaIn_Unfreeze, operation=P_AnaIn_Thermistor.Unfreeze
        IoHwAb_Ev_VolMon_Read: start-on-event=IoHwAb_Re_VolMon_Read, operation=P_VolMon.Read
        IoHwAb_Ev_VolMon_GetStatus: start-on-event=IoHwAb_Re_VolMon_GetStatus, operation=P_VolMon.GetStatus
        IoHwAb_Ev_VolMon_IsThresholdOver: start-on-event=IoHwAb_Re_VolMon_IsThresholdOver, operation=P_VolMon.IsThresholdOver
        IoHwAb_Ev_VolMon_IsThresholdUnder: start-on-event=IoHwAb_Re_VolMon_IsThresholdUnder, operation=P_VolMon.IsThresholdUnder
        IoHwAb_Ev_Icu_NFC_INTERRUPT_SetActivationCondition: start-on-event=IoHwAb_Re_Icu_SetActivationCondition, operation=P_Icu_NFC_INTERRUPT.SetActivationCondition
        IoHwAb_Ev_Icu_NFC_INTERRUPT_DisableNotification: start-on-event=IoHwAb_Re_Icu_DisableNotification, operation=P_Icu_NFC_INTERRUPT.DisableNotification
        IoHwAb_Ev_Icu_NFC_INTERRUPT_EnableNotification: start-on-event=IoHwAb_Re_Icu_EnableNotification, operation=P_Icu_NFC_INTERRUPT.EnableNotification
        IoHwAb_Ev_Icu_NFC_INTERRUPT_GetInputState: start-on-event=IoHwAb_Re_Icu_GetInputState, operation=P_Icu_NFC_INTERRUPT.GetInputState
        IoHwAb_Ev_Icu_NFC_INTERRUPT_StartTimestamp: start-on-event=IoHwAb_Re_Icu_StartTimestamp, operation=P_Icu_NFC_INTERRUPT.StartTimestamp
        IoHwAb_Ev_Icu_NFC_INTERRUPT_StopTimestamp: start-on-event=IoHwAb_Re_Icu_StopTimestamp, operation=P_Icu_NFC_INTERRUPT.StopTimestamp
        IoHwAb_Ev_Icu_NFC_INTERRUPT_GetTimestampIndex: start-on-event=IoHwAb_Re_Icu_GetTimestampIndex, operation=P_Icu_NFC_INTERRUPT.GetTimestampIndex
        IoHwAb_Ev_Icu_NFC_INTERRUPT_ResetEdgeCount: start-on-event=IoHwAb_Re_Icu_ResetEdgeCount, operation=P_Icu_NFC_INTERRUPT.ResetEdgeCount
        IoHwAb_Ev_Icu_NFC_INTERRUPT_EnableEdgeCount: start-on-event=IoHwAb_Re_Icu_EnableEdgeCount, operation=P_Icu_NFC_INTERRUPT.EnableEdgeCount
        IoHwAb_Ev_Icu_NFC_INTERRUPT_DisableEdgeCount: start-on-event=IoHwAb_Re_Icu_DisableEdgeCount, operation=P_Icu_NFC_INTERRUPT.DisableEdgeCount
        IoHwAb_Ev_Icu_NFC_INTERRUPT_GetEdgeNumbers: start-on-event=IoHwAb_Re_Icu_GetEdgeNumbers, operation=P_Icu_NFC_INTERRUPT.GetEdgeNumbers
        IoHwAb_Ev_Icu_NFC_INTERRUPT_EnableEdgeDetection: start-on-event=IoHwAb_Re_Icu_EnableEdgeDetection, operation=P_Icu_NFC_INTERRUPT.EnableEdgeDetection
        IoHwAb_Ev_Icu_NFC_INTERRUPT_DisableEdgeDetection: start-on-event=IoHwAb_Re_Icu_DisableEdgeDetection, operation=P_Icu_NFC_INTERRUPT.DisableEdgeDetection
        IoHwAb_Ev_Icu_NFC_INTERRUPT_StartSignalMeasurement: start-on-event=IoHwAb_Re_Icu_StartSignalMeasurement, operation=P_Icu_NFC_INTERRUPT.StartSignalMeasurement
        IoHwAb_Ev_Icu_NFC_INTERRUPT_StopSignalMeasurement: start-on-event=IoHwAb_Re_Icu_StopSignalMeasurement, operation=P_Icu_NFC_INTERRUPT.StopSignalMeasurement
        IoHwAb_Ev_Icu_NFC_INTERRUPT_GetTimeElapsed: start-on-event=IoHwAb_Re_Icu_GetTimeElapsed, operation=P_Icu_NFC_INTERRUPT.GetTimeElapsed
        IoHwAb_Ev_Icu_NFC_INTERRUPT_GetDutyCycleValues: start-on-event=IoHwAb_Re_Icu_GetDutyCycleValues, operation=P_Icu_NFC_INTERRUPT.GetDutyCycleValues
        IoHwAb_Ev_Icu_P9450_INTB_SetActivationCondition: start-on-event=IoHwAb_Re_Icu_SetActivationCondition, operation=P_Icu_P9450_INTB.SetActivationCondition
        IoHwAb_Ev_Icu_P9450_INTB_DisableNotification: start-on-event=IoHwAb_Re_Icu_DisableNotification, operation=P_Icu_P9450_INTB.DisableNotification
        IoHwAb_Ev_Icu_P9450_INTB_EnableNotification: start-on-event=IoHwAb_Re_Icu_EnableNotification, operation=P_Icu_P9450_INTB.EnableNotification
        IoHwAb_Ev_Icu_P9450_INTB_GetInputState: start-on-event=IoHwAb_Re_Icu_GetInputState, operation=P_Icu_P9450_INTB.GetInputState
        IoHwAb_Ev_Icu_P9450_INTB_StartTimestamp: start-on-event=IoHwAb_Re_Icu_StartTimestamp, operation=P_Icu_P9450_INTB.StartTimestamp
        IoHwAb_Ev_Icu_P9450_INTB_StopTimestamp: start-on-event=IoHwAb_Re_Icu_StopTimestamp, operation=P_Icu_P9450_INTB.StopTimestamp
        IoHwAb_Ev_Icu_P9450_INTB_GetTimestampIndex: start-on-event=IoHwAb_Re_Icu_GetTimestampIndex, operation=P_Icu_P9450_INTB.GetTimestampIndex
        IoHwAb_Ev_Icu_P9450_INTB_ResetEdgeCount: start-on-event=IoHwAb_Re_Icu_ResetEdgeCount, operation=P_Icu_P9450_INTB.ResetEdgeCount
        IoHwAb_Ev_Icu_P9450_INTB_EnableEdgeCount: start-on-event=IoHwAb_Re_Icu_EnableEdgeCount, operation=P_Icu_P9450_INTB.EnableEdgeCount
        IoHwAb_Ev_Icu_P9450_INTB_DisableEdgeCount: start-on-event=IoHwAb_Re_Icu_DisableEdgeCount, operation=P_Icu_P9450_INTB.DisableEdgeCount
        IoHwAb_Ev_Icu_P9450_INTB_GetEdgeNumbers: start-on-event=IoHwAb_Re_Icu_GetEdgeNumbers, operation=P_Icu_P9450_INTB.GetEdgeNumbers
        IoHwAb_Ev_Icu_P9450_INTB_EnableEdgeDetection: start-on-event=IoHwAb_Re_Icu_EnableEdgeDetection, operation=P_Icu_P9450_INTB.EnableEdgeDetection
        IoHwAb_Ev_Icu_P9450_INTB_DisableEdgeDetection: start-on-event=IoHwAb_Re_Icu_DisableEdgeDetection, operation=P_Icu_P9450_INTB.DisableEdgeDetection
        IoHwAb_Ev_Icu_P9450_INTB_StartSignalMeasurement: start-on-event=IoHwAb_Re_Icu_StartSignalMeasurement, operation=P_Icu_P9450_INTB.StartSignalMeasurement
        IoHwAb_Ev_Icu_P9450_INTB_StopSignalMeasurement: start-on-event=IoHwAb_Re_Icu_StopSignalMeasurement, operation=P_Icu_P9450_INTB.StopSignalMeasurement
        IoHwAb_Ev_Icu_P9450_INTB_GetTimeElapsed: start-on-event=IoHwAb_Re_Icu_GetTimeElapsed, operation=P_Icu_P9450_INTB.GetTimeElapsed
        IoHwAb_Ev_Icu_P9450_INTB_GetDutyCycleValues: start-on-event=IoHwAb_Re_Icu_GetDutyCycleValues, operation=P_Icu_P9450_INTB.GetDutyCycleValues
        IoHwAb_Ev_Gpt_NFC_TickTimer_StartTimer: start-on-event=IoHwAb_Re_Gpt_StartTimer, operation=P_Gpt_NFC_TickTimer.StartTimer
        IoHwAb_Ev_Gpt_NFC_TickTimer_StopTimer: start-on-event=IoHwAb_Re_Gpt_StopTimer, operation=P_Gpt_NFC_TickTimer.StopTimer
        IoHwAb_Ev_Gpt_NFC_TickTimer_GetTimeElapsed: start-on-event=IoHwAb_Re_Gpt_GetTimeElapsed, operation=P_Gpt_NFC_TickTimer.GetTimeElapsed
        IoHwAb_Ev_Gpt_NFC_TickTimer_GetTimeRemaining: start-on-event=IoHwAb_Re_Gpt_GetTimeRemaining, operation=P_Gpt_NFC_TickTimer.GetTimeRemaining
        IoHwAb_Ev_Gpt_NFC_TickTimer_DisableNotification: start-on-event=IoHwAb_Re_Gpt_DisableNotification, operation=P_Gpt_NFC_TickTimer.DisableNotification
        IoHwAb_Ev_Gpt_NFC_TickTimer_EnableNotification: start-on-event=IoHwAb_Re_Gpt_EnableNotification, operation=P_Gpt_NFC_TickTimer.EnableNotification
        IoHwAb_Ev_Pwm_AMBER_IND_OUT_SetDutyCycle: start-on-event=IoHwAb_Re_Pwm_SetDutyCycle, operation=P_Pwm_AMBER_IND_OUT.SetDutyCycle
        IoHwAb_Ev_Pwm_AMBER_IND_OUT_SetPeriodAndDuty: start-on-event=IoHwAb_Re_Pwm_SetPeriodAndDuty, operation=P_Pwm_AMBER_IND_OUT.SetPeriodAndDuty
        IoHwAb_Ev_Pwm_AMBER_IND_OUT_SetOutputToIdle: start-on-event=IoHwAb_Re_Pwm_SetOutputToIdle, operation=P_Pwm_AMBER_IND_OUT.SetOutputToIdle
        IoHwAb_Ev_Pwm_AMBER_IND_OUT_GetOutputState: start-on-event=IoHwAb_Re_Pwm_GetOutputState, operation=P_Pwm_AMBER_IND_OUT.GetOutputState
        IoHwAb_Ev_Pwm_AMBER_IND_OUT_DisableNotification: start-on-event=IoHwAb_Re_Pwm_DisableNotification, operation=P_Pwm_AMBER_IND_OUT.DisableNotification
        IoHwAb_Ev_Pwm_AMBER_IND_OUT_EnableNotification: start-on-event=IoHwAb_Re_Pwm_EnableNotification, operation=P_Pwm_AMBER_IND_OUT.EnableNotification
        IoHwAb_Ev_Pwm_FAN_OUT_SetDutyCycle: start-on-event=IoHwAb_Re_Pwm_SetDutyCycle, operation=P_Pwm_FAN_OUT.SetDutyCycle
        IoHwAb_Ev_Pwm_FAN_OUT_SetPeriodAndDuty: start-on-event=IoHwAb_Re_Pwm_SetPeriodAndDuty, operation=P_Pwm_FAN_OUT.SetPeriodAndDuty
        IoHwAb_Ev_Pwm_FAN_OUT_SetOutputToIdle: start-on-event=IoHwAb_Re_Pwm_SetOutputToIdle, operation=P_Pwm_FAN_OUT.SetOutputToIdle
        IoHwAb_Ev_Pwm_FAN_OUT_GetOutputState: start-on-event=IoHwAb_Re_Pwm_GetOutputState, operation=P_Pwm_FAN_OUT.GetOutputState
        IoHwAb_Ev_Pwm_FAN_OUT_DisableNotification: start-on-event=IoHwAb_Re_Pwm_DisableNotification, operation=P_Pwm_FAN_OUT.DisableNotification
        IoHwAb_Ev_Pwm_FAN_OUT_EnableNotification: start-on-event=IoHwAb_Re_Pwm_EnableNotification, operation=P_Pwm_FAN_OUT.EnableNotification
        IoHwAb_Ev_Pwm_GREEN_IND_OUT1_SetDutyCycle: start-on-event=IoHwAb_Re_Pwm_SetDutyCycle, operation=P_Pwm_GREEN_IND_OUT1.SetDutyCycle
        IoHwAb_Ev_Pwm_GREEN_IND_OUT1_SetPeriodAndDuty: start-on-event=IoHwAb_Re_Pwm_SetPeriodAndDuty, operation=P_Pwm_GREEN_IND_OUT1.SetPeriodAndDuty
        IoHwAb_Ev_Pwm_GREEN_IND_OUT1_SetOutputToIdle: start-on-event=IoHwAb_Re_Pwm_SetOutputToIdle, operation=P_Pwm_GREEN_IND_OUT1.SetOutputToIdle
        IoHwAb_Ev_Pwm_GREEN_IND_OUT1_GetOutputState: start-on-event=IoHwAb_Re_Pwm_GetOutputState, operation=P_Pwm_GREEN_IND_OUT1.GetOutputState
        IoHwAb_Ev_Pwm_GREEN_IND_OUT1_DisableNotification: start-on-event=IoHwAb_Re_Pwm_DisableNotification, operation=P_Pwm_GREEN_IND_OUT1.DisableNotification
        IoHwAb_Ev_Pwm_GREEN_IND_OUT1_EnableNotification: start-on-event=IoHwAb_Re_Pwm_EnableNotification, operation=P_Pwm_GREEN_IND_OUT1.EnableNotification
        IoHwAb_Ev_Pwm_GREEN_IND_OUT2_SetDutyCycle: start-on-event=IoHwAb_Re_Pwm_SetDutyCycle, operation=P_Pwm_GREEN_IND_OUT2.SetDutyCycle
        IoHwAb_Ev_Pwm_GREEN_IND_OUT2_SetPeriodAndDuty: start-on-event=IoHwAb_Re_Pwm_SetPeriodAndDuty, operation=P_Pwm_GREEN_IND_OUT2.SetPeriodAndDuty
        IoHwAb_Ev_Pwm_GREEN_IND_OUT2_SetOutputToIdle: start-on-event=IoHwAb_Re_Pwm_SetOutputToIdle, operation=P_Pwm_GREEN_IND_OUT2.SetOutputToIdle
        IoHwAb_Ev_Pwm_GREEN_IND_OUT2_GetOutputState: start-on-event=IoHwAb_Re_Pwm_GetOutputState, operation=P_Pwm_GREEN_IND_OUT2.GetOutputState
        IoHwAb_Ev_Pwm_GREEN_IND_OUT2_DisableNotification: start-on-event=IoHwAb_Re_Pwm_DisableNotification, operation=P_Pwm_GREEN_IND_OUT2.DisableNotification
        IoHwAb_Ev_Pwm_GREEN_IND_OUT2_EnableNotification: start-on-event=IoHwAb_Re_Pwm_EnableNotification, operation=P_Pwm_GREEN_IND_OUT2.EnableNotification
        IoHwAb_Ev_Pwm_GREEN_IND_OUT3_SetDutyCycle: start-on-event=IoHwAb_Re_Pwm_SetDutyCycle, operation=P_Pwm_GREEN_IND_OUT3.SetDutyCycle
        IoHwAb_Ev_Pwm_GREEN_IND_OUT3_SetPeriodAndDuty: start-on-event=IoHwAb_Re_Pwm_SetPeriodAndDuty, operation=P_Pwm_GREEN_IND_OUT3.SetPeriodAndDuty
        IoHwAb_Ev_Pwm_GREEN_IND_OUT3_SetOutputToIdle: start-on-event=IoHwAb_Re_Pwm_SetOutputToIdle, operation=P_Pwm_GREEN_IND_OUT3.SetOutputToIdle
        IoHwAb_Ev_Pwm_GREEN_IND_OUT3_GetOutputState: start-on-event=IoHwAb_Re_Pwm_GetOutputState, operation=P_Pwm_GREEN_IND_OUT3.GetOutputState
        IoHwAb_Ev_Pwm_GREEN_IND_OUT3_DisableNotification: start-on-event=IoHwAb_Re_Pwm_DisableNotification, operation=P_Pwm_GREEN_IND_OUT3.DisableNotification
        IoHwAb_Ev_Pwm_GREEN_IND_OUT3_EnableNotification: start-on-event=IoHwAb_Re_Pwm_EnableNotification, operation=P_Pwm_GREEN_IND_OUT3.EnableNotification
      port-api-options:
        {enable-take-address=false, indirect-api=false, port-defined-argument-value{value=0, value-type=IoHwAb_IndexType}, port=P_DigDir_BCAN_WakeUp_INT}
        {enable-take-address=false, indirect-api=false, port-defined-argument-value{value=1, value-type=IoHwAb_IndexType}, port=P_DigDir_FAN_DIAG}
        {enable-take-address=false, indirect-api=false, port-defined-argument-value{value=2, value-type=IoHwAb_IndexType}, port=P_DigDir_LCAN_WakeUp_INT}
        {enable-take-address=false, indirect-api=false, port-defined-argument-value{value=3, value-type=IoHwAb_IndexType}, port=P_DigDir_NFC_INTERRUPT_INT}
        {enable-take-address=false, indirect-api=false, port-defined-argument-value{value=4, value-type=IoHwAb_IndexType}, port=P_DigDir_NFC_OPTION}
        {enable-take-address=false, indirect-api=false, port-defined-argument-value{value=5, value-type=IoHwAb_IndexType}, port=P_DigDir_P9450_INTB_INT}
        {enable-take-address=false, indirect-api=false, port-defined-argument-value{value=6, value-type=IoHwAb_IndexType}, port=P_DigDir_SPI_CS}
        {enable-take-address=false, indirect-api=false, port-defined-argument-value{value=7, value-type=IoHwAb_IndexType}, port=P_DigDir_VBATSW_EN}
        {enable-take-address=false, indirect-api=false, port-defined-argument-value{value=8, value-type=IoHwAb_IndexType}, port=P_DigDir_VN7140AS_IN}
        {enable-take-address=false, indirect-api=false, port-defined-argument-value{value=9, value-type=IoHwAb_IndexType}, port=P_DigDir_VN7140AS_MULTI}
        {enable-take-address=false, indirect-api=false, port-defined-argument-value{value=10, value-type=IoHwAb_IndexType}, port=P_DigDir_VN7140AS_SEN}
        {enable-take-address=false, indirect-api=false, port-defined-argument-value{value=11, value-type=IoHwAb_IndexType}, port=P_IoHwAbDigitalDirectLogical_BCAN_RX}
        {enable-take-address=false, indirect-api=false, port-defined-argument-value{value=12, value-type=IoHwAb_IndexType}, port=P_IoHwAbDigitalDirectLogical_LOCALCAN_RX}
        {enable-take-address=false, indirect-api=false, port-defined-argument-value{value=0, value-type=IoHwAb_IndexType}, port=P_AnaInDir_ACC_Real}
        {enable-take-address=false, indirect-api=false, port-defined-argument-value{value=1, value-type=IoHwAb_IndexType}, port=P_AnaInDir_Battery_Real}
        {enable-take-address=false, indirect-api=false, port-defined-argument-value{value=2, value-type=IoHwAb_IndexType}, port=P_AnaInDir_Thermistor}
        {enable-take-address=false, indirect-api=false, port-defined-argument-value{value=3, value-type=IoHwAb_IndexType}, port=P_AnaInDir_Thermistor2}
        {enable-take-address=false, indirect-api=false, port-defined-argument-value{value=4, value-type=IoHwAb_IndexType}, port=P_AnaInDir_Thermistor3}
        {enable-take-address=false, indirect-api=false, port-defined-argument-value{value=0, value-type=IoHwAb_IndexType}, port=P_AnaIn_ACC_Real}
        {enable-take-address=false, indirect-api=false, port-defined-argument-value{value=1, value-type=IoHwAb_IndexType}, port=P_AnaIn_Battery_Real}
        {enable-take-address=false, indirect-api=false, port-defined-argument-value{value=2, value-type=IoHwAb_IndexType}, port=P_AnaIn_Thermistor}
        {enable-take-address=false, indirect-api=false, port-defined-argument-value{value=0, value-type=IoHwAb_IndexType}, port=P_Icu_NFC_INTERRUPT}
        {enable-take-address=false, indirect-api=false, port-defined-argument-value{value=1, value-type=IoHwAb_IndexType}, port=P_Icu_P9450_INTB}
        {enable-take-address=false, indirect-api=false, port-defined-argument-value{value=0, value-type=IoHwAb_IndexType}, port=P_Gpt_NFC_TickTimer}
        {enable-take-address=false, indirect-api=false, port-defined-argument-value{value=0, value-type=IoHwAb_IndexType}, port=P_Pwm_AMBER_IND_OUT}
        {enable-take-address=false, indirect-api=false, port-defined-argument-value{value=1, value-type=IoHwAb_IndexType}, port=P_Pwm_FAN_OUT}
        {enable-take-address=false, indirect-api=false, port-defined-argument-value{value=2, value-type=IoHwAb_IndexType}, port=P_Pwm_GREEN_IND_OUT1}
        {enable-take-address=false, indirect-api=false, port-defined-argument-value{value=3, value-type=IoHwAb_IndexType}, port=P_Pwm_GREEN_IND_OUT2}
        {enable-take-address=false, indirect-api=false, port-defined-argument-value{value=4, value-type=IoHwAb_IndexType}, port=P_Pwm_GREEN_IND_OUT3}
      47 x runnable:
        IoHwAb_Re_DigDir_ReadDirect: can-be-invoked-concurrently=true, symbol=IoHwAb_DigDirReadDirect
        IoHwAb_Re_DigDir_WriteDirect: can-be-invoked-concurrently=true, symbol=IoHwAb_DigDirWriteDirect
        IoHwAb_Re_DigDir_SetToInput: can-be-invoked-concurrently=true, symbol=IoHwAb_DigDirSetToInput
        IoHwAb_Re_DigDir_SetToOutput: can-be-invoked-concurrently=true, symbol=IoHwAb_DigDirSetToOutput
        IoHwAb_Re_DigDir_IsInput: can-be-invoked-concurrently=true, symbol=IoHwAb_DigDirIsInput
        IoHwAb_Re_DigDir_IsOutput: can-be-invoked-concurrently=true, symbol=IoHwAb_DigDirIsOutput
        IoHwAb_Re_AnaInDir_ReadDirect: symbol=IoHwAb_AnaInDirReadDirect
        IoHwAb_Re_AnaIn_Read: can-be-invoked-concurrently=true, symbol=IoHwAb_AnaInRead
        IoHwAb_Re_AnaIn_Freeze: can-be-invoked-concurrently=true, symbol=IoHwAb_AnaInFreeze
        IoHwAb_Re_AnaIn_Unfreeze: can-be-invoked-concurrently=true, symbol=IoHwAb_AnaInUnfreeze
        IoHwAb_Re_VolMon_Read: can-be-invoked-concurrently=true, symbol=IoHwAb_VolMonRead
        IoHwAb_Re_VolMon_GetStatus: can-be-invoked-concurrently=true, symbol=IoHwAb_VolMonGetStatus
        IoHwAb_Re_VolMon_IsThresholdOver: can-be-invoked-concurrently=true, symbol=IoHwAb_VolMonIsThresholdOver
        IoHwAb_Re_VolMon_IsThresholdUnder: can-be-invoked-concurrently=true, symbol=IoHwAb_VolMonIsThresholdUnder
        IoHwAb_Re_VolMon_Notification: can-be-invoked-concurrently=true, symbol=IoHwAb_VolMonNotification
          sync call IoHwAb_Cp_VolMon_Cbk: operation=R_VolMon_Cbk.Notification, timeout=0.0
        IoHwAb_Re_Icu_SetActivationCondition: can-be-invoked-concurrently=true, symbol=IoHwAb_IcuSetActivationCondition
        IoHwAb_Re_Icu_DisableNotification: can-be-invoked-concurrently=true, symbol=IoHwAb_IcuDisableNotification
        IoHwAb_Re_Icu_EnableNotification: can-be-invoked-concurrently=true, symbol=IoHwAb_IcuEnableNotification
        IoHwAb_Re_Icu_GetInputState: can-be-invoked-concurrently=true, symbol=IoHwAb_IcuGetInputState
        IoHwAb_Re_Icu_StartTimestamp: can-be-invoked-concurrently=true, symbol=IoHwAb_IcuStartTimestamp
        IoHwAb_Re_Icu_StopTimestamp: can-be-invoked-concurrently=true, symbol=IoHwAb_IcuStopTimestamp
        IoHwAb_Re_Icu_GetTimestampIndex: can-be-invoked-concurrently=true, symbol=IoHwAb_IcuGetTimestampIndex
        IoHwAb_Re_Icu_ResetEdgeCount: can-be-invoked-concurrently=true, symbol=IoHwAb_IcuResetEdgeCount
        IoHwAb_Re_Icu_EnableEdgeCount: can-be-invoked-concurrently=true, symbol=IoHwAb_IcuEnableEdgeCount
        IoHwAb_Re_Icu_DisableEdgeCount: can-be-invoked-concurrently=true, symbol=IoHwAb_IcuDisableEdgeCount
        IoHwAb_Re_Icu_GetEdgeNumbers: can-be-invoked-concurrently=true, symbol=IoHwAb_IcuGetEdgeNumbers
        IoHwAb_Re_Icu_EnableEdgeDetection: can-be-invoked-concurrently=true, symbol=IoHwAb_IcuEnableEdgeDetection
        IoHwAb_Re_Icu_DisableEdgeDetection: can-be-invoked-concurrently=true, symbol=IoHwAb_IcuDisableEdgeDetection
        IoHwAb_Re_Icu_StartSignalMeasurement: can-be-invoked-concurrently=true, symbol=IoHwAb_IcuStartSignalMeasurement
        IoHwAb_Re_Icu_StopSignalMeasurement: can-be-invoked-concurrently=true, symbol=IoHwAb_IcuStopSignalMeasurement
        IoHwAb_Re_Icu_GetTimeElapsed: can-be-invoked-concurrently=true, symbol=IoHwAb_IcuGetTimeElapsed
        IoHwAb_Re_Icu_GetDutyCycleValues: can-be-invoked-concurrently=true, symbol=IoHwAb_IcuGetDutyCycleValues
        IoHwAb_Re_Icu_IcuSignalEdgeDetection_NFC_INTERRUPT_Cbk_Cbk: can-be-invoked-concurrently=true, symbol=IcuSignalEdgeDetection_NFC_INTERRUPT_Cbk
          sync call IoHwAb_Cp_Icu_Icu_NFC_INTERRUPT_Cbk: operation=R_Icu_NFC_INTERRUPT_Cbk.Notification, timeout=0.0
        IoHwAb_Re_Icu_IcuSignalEdgeDetection_P9450_INTB_Cbk_Cbk: can-be-invoked-concurrently=true, symbol=IcuSignalEdgeDetection_P9450_INTB_Cbk
          sync call IoHwAb_Cp_Icu_Icu_P9450_INTB_Cbk: operation=R_Icu_P9450_INTB_Cbk.Notification, timeout=0.0
        IoHwAb_Re_Gpt_StartTimer: can-be-invoked-concurrently=true, symbol=IoHwAb_GptStartTimer
        IoHwAb_Re_Gpt_StopTimer: can-be-invoked-concurrently=true, symbol=IoHwAb_GptStopTimer
        IoHwAb_Re_Gpt_GetTimeElapsed: can-be-invoked-concurrently=true, symbol=IoHwAb_GptGetTimeElapsed
        IoHwAb_Re_Gpt_GetTimeRemaining: can-be-invoked-concurrently=true, symbol=IoHwAb_GptGetTimeRemaining
        IoHwAb_Re_Gpt_DisableNotification: can-be-invoked-concurrently=true, symbol=IoHwAb_GptDisableNotification
        IoHwAb_Re_Gpt_EnableNotification: can-be-invoked-concurrently=true, symbol=IoHwAb_GptEnableNotification
        IoHwAb_Re_Gpt_GptChannelConfiguration_IoHwAbTest_Cbk_Cbk: can-be-invoked-concurrently=true, symbol=GptChannelConfiguration_IoHwAbTest_Cbk
          sync call IoHwAb_Cp_Gpt_Gpt_NFC_TickTimer_Cbk: operation=R_Gpt_NFC_TickTimer_Cbk.Notification, timeout=0.0
        IoHwAb_Re_Pwm_SetDutyCycle: can-be-invoked-concurrently=true, symbol=IoHwAb_PwmSetDutyCycle
        IoHwAb_Re_Pwm_SetPeriodAndDuty: can-be-invoked-concurrently=true, symbol=IoHwAb_PwmSetPeriodAndDuty
        IoHwAb_Re_Pwm_SetOutputToIdle: can-be-invoked-concurrently=true, symbol=IoHwAb_PwmSetOutputToIdle
        IoHwAb_Re_Pwm_GetOutputState: can-be-invoked-concurrently=true, symbol=IoHwAb_PwmGetOutputState
        IoHwAb_Re_Pwm_DisableNotification: can-be-invoked-concurrently=true, symbol=IoHwAb_PwmDisableNotification
        IoHwAb_Re_Pwm_EnableNotification: can-be-invoked-concurrently=true, symbol=IoHwAb_PwmEnableNotification
  swc implementation SwcImplementation_IoHwAb: swc-bsw-mapping=SwcBswMapping_IoHwAb, behavior=IB_IoHwAb
